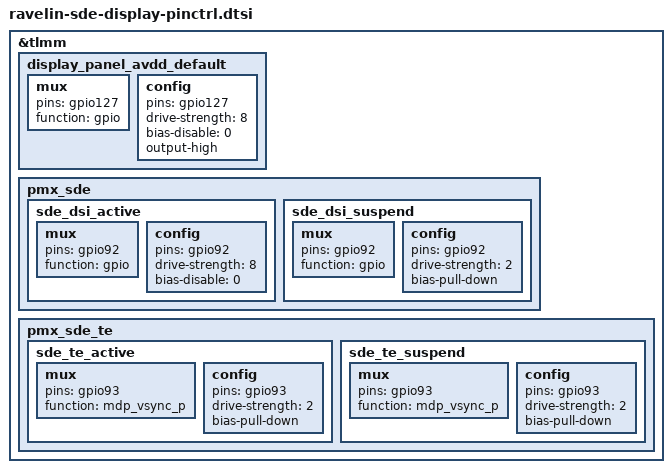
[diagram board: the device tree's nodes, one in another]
&tlmm {
	display_panel_avdd_default: display_panel_avdd_default {
		mux {
			pins = "gpio127";
			function = "gpio";
		};

		config {
			pins = "gpio127";
			drive-strength = <8>;
			bias-disable = <0>;
			output-high;
		};
	};

	pmx_sde: pmx_sde {
		sde_dsi_active: sde_dsi_active {
			mux {
				pins = "gpio92";
				function = "gpio";
			};

			config {
				pins = "gpio92";
				drive-strength = <8>;   /* 8 mA */
				bias-disable = <0>;   /* no pull */
			};
		};

		sde_dsi_suspend: sde_dsi_suspend {
			mux {
				pins = "gpio92";
				function = "gpio";
			};

			config {
				pins = "gpio92";
				drive-strength = <2>;   /* 2 mA */
				bias-pull-down;         /* PULL DOWN */
			};
		};
	};

	pmx_sde_te: pmx_sde_te {
		sde_te_active: sde_te_active {
			mux {
				pins = "gpio93";
				function = "mdp_vsync_p";
			};

			config {
				pins = "gpio93";
				drive-strength = <2>;   /* 2 mA */
				bias-pull-down;         /* PULL DOWN */
			};
		};

		sde_te_suspend: sde_te_suspend {
			mux {
				pins = "gpio93";
				function = "mdp_vsync_p";
			};

			config {
				pins = "gpio93";
				drive-strength = <2>;   /* 2 mA */
				bias-pull-down;         /* PULL DOWN */
			};
		};
	};
};
